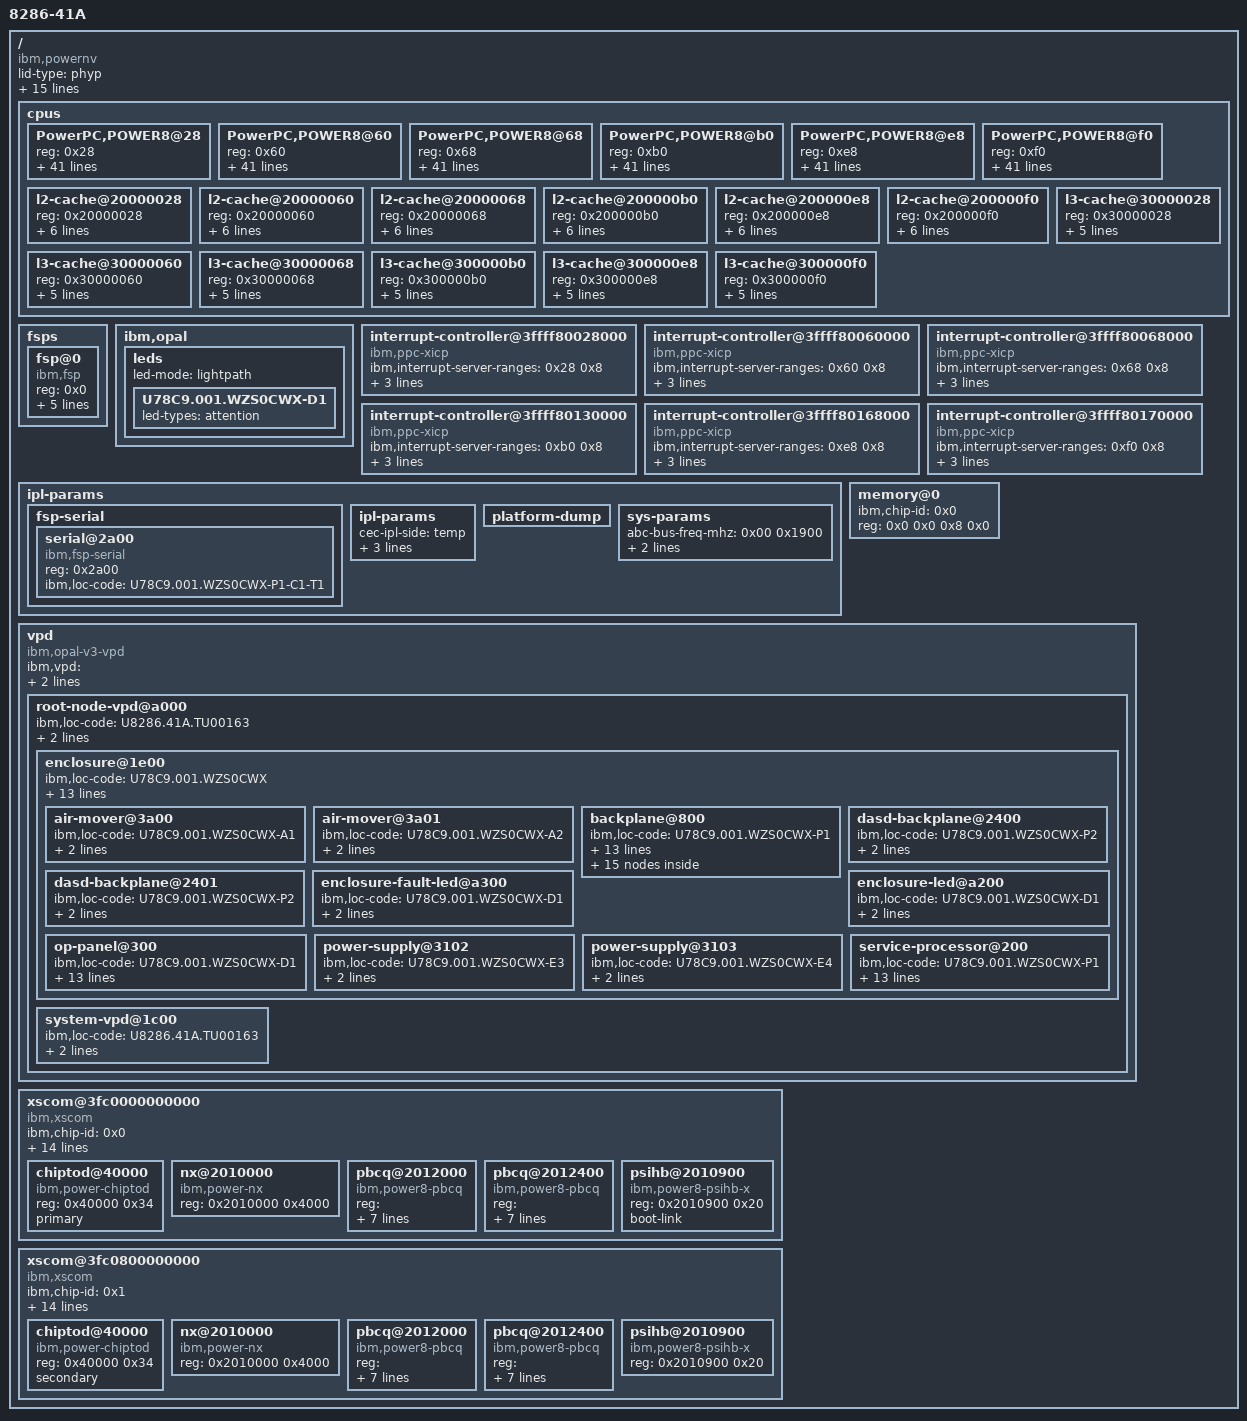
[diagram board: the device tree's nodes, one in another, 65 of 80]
/dts-v1/;

/memreserve/	0x00000007fd510000 0x0000000000190000;
/memreserve/	0x00000007fd6a0000 0x0000000000060000;
/memreserve/	0x00000007fd700000 0x0000000000100000;
/ {
	phandle = <0x1>;
	#address-cells = <0x2>;
	#size-cells = <0x2>;
	lid-type = "phyp";
	compatible = "ibm,powernv", "ibm,firenze";
	nest-frequency = <0x0 0x77359400>;
	vendor = "IBM";
	ibm,io-base-loc-code = "U78C9.001.WZS0CWX-P1";
	ibm,vpd-lx-info = <0x0 0x31000401 0x300043>;
	model = "8286-41A";
	system-id = "TU00163";
	system-brand = "S0";
	model-name = "IBM Power System S814";
	ibm,hbrt-mini-fdt = <0xcafebeef 0x1000 0x31ce42d>;
	reserved-ranges = <0x7 0xfd700000 0x0 0x100000 0x7 0xfd6a0000 0x0 0x60000 0x7 0xfd510000 0x0 0x190000>;
	reserved-names = "ibm,hbrt-vpd-image", "ibm,hbrt-target-image", "ibm,hbrt-code-image";
	ibm,enabled-idle-states = "nap", "fast-sleep", "rvwinkle";

	cpus {
		phandle = <0x22>;
		#address-cells = <0x1>;
		#size-cells = <0x0>;

		PowerPC,POWER8@28 {
			phandle = <0x23>;
			device_type = "cpu";
			status = "okay";
			reg = <0x28>;
			cpu-version = <0x4b0201>;
			64-bit;
			32-64-bridge;
			graphics;
			general-purpose;
			ibm,processor-segment-sizes = <0x1c 0x28 0xffffffff 0xffffffff>;
			ibm,processor-page-sizes = <0xc 0x10 0x18 0x22>;
			ibm,segment-page-sizes = <0xc 0x0 0x3 0xc 0x0 0x10 0x7 0x18 0x38 0x10 0x110 0x2 0x10 0x1 0x18 0x8 0x18 0x100 0x1 0x18 0x0 0x22 0x120 0x1 0x22 0x3>;
			ibm,pa-features = [18 00 f6 3f c7 c0 80 d0 80 00 00 00 00 00 00 00 00 00 80 00 80 00 80 00 80 00];
			ibm,slb-size = <0x20>;
			ibm,vmx = <0x2>;
			ibm,dfp = <0x2>;
			ibm,purr = <0x1>;
			ibm,spurr = <0x1>;
			clock-frequency = <0xb45d1880>;
			ibm,extended-clock-frequency = <0x0 0xb45d1880>;
			timebase-frequency = <0x1e848000>;
			ibm,extended-timebase-frequency = <0x0 0x1e848000>;
			reservation-granule-size = <0x80>;
			d-tlb-size = <0x800>;
			i-tlb-size = <0x0>;
			tlb-size = <0x800>;
			d-tlb-sets = <0x4>;
			i-tlb-sets = <0x0>;
			tlb-sets = <0x4>;
			d-cache-block-size = <0x80>;
			i-cache-block-size = <0x80>;
			d-cache-size = <0x10000>;
			i-cache-size = <0x8000>;
			i-cache-sets = <0x4>;
			d-cache-sets = <0x8>;
			performance-monitor = <0x0 0x1>;
			l2-cache = <0x24>;
			ibm,pir = <0x28>;
			ibm,chip-id = <0x0>;
			ibm,ppc-interrupt-server#s = <0x28 0x29 0x2a 0x2b 0x2c 0x2d 0x2e 0x2f>;
		};

		PowerPC,POWER8@60 {
			phandle = <0x27>;
			device_type = "cpu";
			status = "okay";
			reg = <0x60>;
			cpu-version = <0x4b0201>;
			64-bit;
			32-64-bridge;
			graphics;
			general-purpose;
			ibm,processor-segment-sizes = <0x1c 0x28 0xffffffff 0xffffffff>;
			ibm,processor-page-sizes = <0xc 0x10 0x18 0x22>;
			ibm,segment-page-sizes = <0xc 0x0 0x3 0xc 0x0 0x10 0x7 0x18 0x38 0x10 0x110 0x2 0x10 0x1 0x18 0x8 0x18 0x100 0x1 0x18 0x0 0x22 0x120 0x1 0x22 0x3>;
			ibm,pa-features = [18 00 f6 3f c7 c0 80 d0 80 00 00 00 00 00 00 00 00 00 80 00 80 00 80 00 80 00];
			ibm,slb-size = <0x20>;
			ibm,vmx = <0x2>;
			ibm,dfp = <0x2>;
			ibm,purr = <0x1>;
			ibm,spurr = <0x1>;
			clock-frequency = <0xb45d1880>;
			ibm,extended-clock-frequency = <0x0 0xb45d1880>;
			timebase-frequency = <0x1e848000>;
			ibm,extended-timebase-frequency = <0x0 0x1e848000>;
			reservation-granule-size = <0x80>;
			d-tlb-size = <0x800>;
			i-tlb-size = <0x0>;
			tlb-size = <0x800>;
			d-tlb-sets = <0x4>;
			i-tlb-sets = <0x0>;
			tlb-sets = <0x4>;
			d-cache-block-size = <0x80>;
			i-cache-block-size = <0x80>;
			d-cache-size = <0x10000>;
			i-cache-size = <0x8000>;
			i-cache-sets = <0x4>;
			d-cache-sets = <0x8>;
			performance-monitor = <0x0 0x1>;
			l2-cache = <0x28>;
			ibm,pir = <0x60>;
			ibm,chip-id = <0x0>;
			ibm,ppc-interrupt-server#s = <0x60 0x61 0x62 0x63 0x64 0x65 0x66 0x67>;
		};

		PowerPC,POWER8@68 {
			phandle = <0x2b>;
			device_type = "cpu";
			status = "okay";
			reg = <0x68>;
			cpu-version = <0x4b0201>;
			64-bit;
			32-64-bridge;
			graphics;
			general-purpose;
			ibm,processor-segment-sizes = <0x1c 0x28 0xffffffff 0xffffffff>;
			ibm,processor-page-sizes = <0xc 0x10 0x18 0x22>;
			ibm,segment-page-sizes = <0xc 0x0 0x3 0xc 0x0 0x10 0x7 0x18 0x38 0x10 0x110 0x2 0x10 0x1 0x18 0x8 0x18 0x100 0x1 0x18 0x0 0x22 0x120 0x1 0x22 0x3>;
			ibm,pa-features = [18 00 f6 3f c7 c0 80 d0 80 00 00 00 00 00 00 00 00 00 80 00 80 00 80 00 80 00];
			ibm,slb-size = <0x20>;
			ibm,vmx = <0x2>;
			ibm,dfp = <0x2>;
			ibm,purr = <0x1>;
			ibm,spurr = <0x1>;
			clock-frequency = <0xb45d1880>;
			ibm,extended-clock-frequency = <0x0 0xb45d1880>;
			timebase-frequency = <0x1e848000>;
			ibm,extended-timebase-frequency = <0x0 0x1e848000>;
			reservation-granule-size = <0x80>;
			d-tlb-size = <0x800>;
			i-tlb-size = <0x0>;
			tlb-size = <0x800>;
			d-tlb-sets = <0x4>;
			i-tlb-sets = <0x0>;
			tlb-sets = <0x4>;
			d-cache-block-size = <0x80>;
			i-cache-block-size = <0x80>;
			d-cache-size = <0x10000>;
			i-cache-size = <0x8000>;
			i-cache-sets = <0x4>;
			d-cache-sets = <0x8>;
			performance-monitor = <0x0 0x1>;
			l2-cache = <0x2c>;
			ibm,pir = <0x68>;
			ibm,chip-id = <0x0>;
			ibm,ppc-interrupt-server#s = <0x68 0x69 0x6a 0x6b 0x6c 0x6d 0x6e 0x6f>;
		};

		PowerPC,POWER8@b0 {
			phandle = <0x2f>;
			device_type = "cpu";
			status = "okay";
			reg = <0xb0>;
			cpu-version = <0x4b0201>;
			64-bit;
			32-64-bridge;
			graphics;
			general-purpose;
			ibm,processor-segment-sizes = <0x1c 0x28 0xffffffff 0xffffffff>;
			ibm,processor-page-sizes = <0xc 0x10 0x18 0x22>;
			ibm,segment-page-sizes = <0xc 0x0 0x3 0xc 0x0 0x10 0x7 0x18 0x38 0x10 0x110 0x2 0x10 0x1 0x18 0x8 0x18 0x100 0x1 0x18 0x0 0x22 0x120 0x1 0x22 0x3>;
			ibm,pa-features = [18 00 f6 3f c7 c0 80 d0 80 00 00 00 00 00 00 00 00 00 80 00 80 00 80 00 80 00];
			ibm,slb-size = <0x20>;
			ibm,vmx = <0x2>;
			ibm,dfp = <0x2>;
			ibm,purr = <0x1>;
			ibm,spurr = <0x1>;
			clock-frequency = <0xb45d1880>;
			ibm,extended-clock-frequency = <0x0 0xb45d1880>;
			timebase-frequency = <0x1e848000>;
			ibm,extended-timebase-frequency = <0x0 0x1e848000>;
			reservation-granule-size = <0x80>;
			d-tlb-size = <0x800>;
			i-tlb-size = <0x0>;
			tlb-size = <0x800>;
			d-tlb-sets = <0x4>;
			i-tlb-sets = <0x0>;
			tlb-sets = <0x4>;
			d-cache-block-size = <0x80>;
			i-cache-block-size = <0x80>;
			d-cache-size = <0x10000>;
			i-cache-size = <0x8000>;
			i-cache-sets = <0x4>;
			d-cache-sets = <0x8>;
			performance-monitor = <0x0 0x1>;
			l2-cache = <0x30>;
			ibm,pir = <0xb0>;
			ibm,chip-id = <0x1>;
			ibm,ppc-interrupt-server#s = <0xb0 0xb1 0xb2 0xb3 0xb4 0xb5 0xb6 0xb7>;
		};

		PowerPC,POWER8@e8 {
			phandle = <0x33>;
			device_type = "cpu";
			status = "okay";
			reg = <0xe8>;
			cpu-version = <0x4b0201>;
			64-bit;
			32-64-bridge;
			graphics;
			general-purpose;
			ibm,processor-segment-sizes = <0x1c 0x28 0xffffffff 0xffffffff>;
			ibm,processor-page-sizes = <0xc 0x10 0x18 0x22>;
			ibm,segment-page-sizes = <0xc 0x0 0x3 0xc 0x0 0x10 0x7 0x18 0x38 0x10 0x110 0x2 0x10 0x1 0x18 0x8 0x18 0x100 0x1 0x18 0x0 0x22 0x120 0x1 0x22 0x3>;
			ibm,pa-features = [18 00 f6 3f c7 c0 80 d0 80 00 00 00 00 00 00 00 00 00 80 00 80 00 80 00 80 00];
			ibm,slb-size = <0x20>;
			ibm,vmx = <0x2>;
			ibm,dfp = <0x2>;
			ibm,purr = <0x1>;
			ibm,spurr = <0x1>;
			clock-frequency = <0xb45d1880>;
			ibm,extended-clock-frequency = <0x0 0xb45d1880>;
			timebase-frequency = <0x1e848000>;
			ibm,extended-timebase-frequency = <0x0 0x1e848000>;
			reservation-granule-size = <0x80>;
			d-tlb-size = <0x800>;
			i-tlb-size = <0x0>;
			tlb-size = <0x800>;
			d-tlb-sets = <0x4>;
			i-tlb-sets = <0x0>;
			tlb-sets = <0x4>;
			d-cache-block-size = <0x80>;
			i-cache-block-size = <0x80>;
			d-cache-size = <0x10000>;
			i-cache-size = <0x8000>;
			i-cache-sets = <0x4>;
			d-cache-sets = <0x8>;
			performance-monitor = <0x0 0x1>;
			l2-cache = <0x34>;
			ibm,pir = <0xe8>;
			ibm,chip-id = <0x1>;
			ibm,ppc-interrupt-server#s = <0xe8 0xe9 0xea 0xeb 0xec 0xed 0xee 0xef>;
		};

		PowerPC,POWER8@f0 {
			phandle = <0x37>;
			device_type = "cpu";
			status = "okay";
			reg = <0xf0>;
			cpu-version = <0x4b0201>;
			64-bit;
			32-64-bridge;
			graphics;
			general-purpose;
			ibm,processor-segment-sizes = <0x1c 0x28 0xffffffff 0xffffffff>;
			ibm,processor-page-sizes = <0xc 0x10 0x18 0x22>;
			ibm,segment-page-sizes = <0xc 0x0 0x3 0xc 0x0 0x10 0x7 0x18 0x38 0x10 0x110 0x2 0x10 0x1 0x18 0x8 0x18 0x100 0x1 0x18 0x0 0x22 0x120 0x1 0x22 0x3>;
			ibm,pa-features = [18 00 f6 3f c7 c0 80 d0 80 00 00 00 00 00 00 00 00 00 80 00 80 00 80 00 80 00];
			ibm,slb-size = <0x20>;
			ibm,vmx = <0x2>;
			ibm,dfp = <0x2>;
			ibm,purr = <0x1>;
			ibm,spurr = <0x1>;
			clock-frequency = <0xb45d1880>;
			ibm,extended-clock-frequency = <0x0 0xb45d1880>;
			timebase-frequency = <0x1e848000>;
			ibm,extended-timebase-frequency = <0x0 0x1e848000>;
			reservation-granule-size = <0x80>;
			d-tlb-size = <0x800>;
			i-tlb-size = <0x0>;
			tlb-size = <0x800>;
			d-tlb-sets = <0x4>;
			i-tlb-sets = <0x0>;
			tlb-sets = <0x4>;
			d-cache-block-size = <0x80>;
			i-cache-block-size = <0x80>;
			d-cache-size = <0x10000>;
			i-cache-size = <0x8000>;
			i-cache-sets = <0x4>;
			d-cache-sets = <0x8>;
			performance-monitor = <0x0 0x1>;
			l2-cache = <0x38>;
			ibm,pir = <0xf0>;
			ibm,chip-id = <0x1>;
			ibm,ppc-interrupt-server#s = <0xf0 0xf1 0xf2 0xf3 0xf4 0xf5 0xf6 0xf7>;
		};

		l2-cache@20000028 {
			phandle = <0x24>;
			device_type = "cache";
			reg = <0x20000028>;
			status = "okay";
			cache-unified;
			d-cache-sets = <0x8>;
			i-cache-sets = <0x8>;
			d-cache-size = <0x80000>;
			i-cache-size = <0x80000>;
			l2-cache = <0x25>;
		};

		l2-cache@20000060 {
			phandle = <0x28>;
			device_type = "cache";
			reg = <0x20000060>;
			status = "okay";
			cache-unified;
			d-cache-sets = <0x8>;
			i-cache-sets = <0x8>;
			d-cache-size = <0x80000>;
			i-cache-size = <0x80000>;
			l2-cache = <0x29>;
		};

		l2-cache@20000068 {
			phandle = <0x2c>;
			device_type = "cache";
			reg = <0x20000068>;
			status = "okay";
			cache-unified;
			d-cache-sets = <0x8>;
			i-cache-sets = <0x8>;
			d-cache-size = <0x80000>;
			i-cache-size = <0x80000>;
			l2-cache = <0x2d>;
		};

		l2-cache@200000b0 {
			phandle = <0x30>;
			device_type = "cache";
			reg = <0x200000b0>;
			status = "okay";
			cache-unified;
			d-cache-sets = <0x8>;
			i-cache-sets = <0x8>;
			d-cache-size = <0x80000>;
			i-cache-size = <0x80000>;
			l2-cache = <0x31>;
		};

		l2-cache@200000e8 {
			phandle = <0x34>;
			device_type = "cache";
			reg = <0x200000e8>;
			status = "okay";
			cache-unified;
			d-cache-sets = <0x8>;
			i-cache-sets = <0x8>;
			d-cache-size = <0x80000>;
			i-cache-size = <0x80000>;
			l2-cache = <0x35>;
		};

		l2-cache@200000f0 {
			phandle = <0x38>;
			device_type = "cache";
			reg = <0x200000f0>;
			status = "okay";
			cache-unified;
			d-cache-sets = <0x8>;
			i-cache-sets = <0x8>;
			d-cache-size = <0x80000>;
			i-cache-size = <0x80000>;
			l2-cache = <0x39>;
		};

		l3-cache@30000028 {
			phandle = <0x25>;
			device_type = "cache";
			reg = <0x30000028>;
			status = "okay";
			cache-unified;
			d-cache-sets = <0x8>;
			i-cache-sets = <0x8>;
			d-cache-size = <0x800000>;
			i-cache-size = <0x800000>;
		};

		l3-cache@30000060 {
			phandle = <0x29>;
			device_type = "cache";
			reg = <0x30000060>;
			status = "okay";
			cache-unified;
			d-cache-sets = <0x8>;
			i-cache-sets = <0x8>;
			d-cache-size = <0x800000>;
			i-cache-size = <0x800000>;
		};

		l3-cache@30000068 {
			phandle = <0x2d>;
			device_type = "cache";
			reg = <0x30000068>;
			status = "okay";
			cache-unified;
			d-cache-sets = <0x8>;
			i-cache-sets = <0x8>;
			d-cache-size = <0x800000>;
			i-cache-size = <0x800000>;
		};

		l3-cache@300000b0 {
			phandle = <0x31>;
			device_type = "cache";
			reg = <0x300000b0>;
			status = "okay";
			cache-unified;
			d-cache-sets = <0x8>;
			i-cache-sets = <0x8>;
			d-cache-size = <0x800000>;
			i-cache-size = <0x800000>;
		};

		l3-cache@300000e8 {
			phandle = <0x35>;
			device_type = "cache";
			reg = <0x300000e8>;
			status = "okay";
			cache-unified;
			d-cache-sets = <0x8>;
			i-cache-sets = <0x8>;
			d-cache-size = <0x800000>;
			i-cache-size = <0x800000>;
		};

		l3-cache@300000f0 {
			phandle = <0x39>;
			device_type = "cache";
			reg = <0x300000f0>;
			status = "okay";
			cache-unified;
			d-cache-sets = <0x8>;
			i-cache-sets = <0x8>;
			d-cache-size = <0x800000>;
			i-cache-size = <0x800000>;
		};
	};

	fsps {
		phandle = <0x46>;
		#address-cells = <0x1>;
		#size-cells = <0x0>;

		fsp@0 {
			phandle = <0x47>;
			reg = <0x0>;
			compatible = "ibm,fsp", "ibm,fsp2";
			reg-offset = <0xb0011000>;
			hw-version = <0x2>;
			sw-version = <0x1>;
			primary;
			ibm,psi-links = <0x0>;
		};
	};

	ibm,opal {
		phandle = <0x20>;

		leds {
			phandle = <0x21>;
			led-mode = "lightpath";

			U78C9.001.WZS0CWX-D1 {
				phandle = <0x7000015>;
				led-types = "attention";
			};
		};
	};

	interrupt-controller@3ffff80028000 {
		phandle = <0x26>;
		compatible = "ibm,ppc-xicp", "IBM,power8-icp";
		ibm,interrupt-server-ranges = <0x28 0x8>;
		interrupt-controller;
		reg = <0x3ffff 0x80028000 0x0 0x1000 0x3ffff 0x80029000 0x0 0x1000 0x3ffff 0x8002a000 0x0 0x1000 0x3ffff 0x8002b000 0x0 0x1000 0x3ffff 0x8002c000 0x0 0x1000 0x3ffff 0x8002d000 0x0 0x1000 0x3ffff 0x8002e000 0x0 0x1000 0x3ffff 0x8002f000 0x0 0x1000>;
		#address-cells = <0x0>;
		device_type = "PowerPC-External-Interrupt-Presentation";
	};

	interrupt-controller@3ffff80060000 {
		phandle = <0x2a>;
		compatible = "ibm,ppc-xicp", "IBM,power8-icp";
		ibm,interrupt-server-ranges = <0x60 0x8>;
		interrupt-controller;
		reg = <0x3ffff 0x80060000 0x0 0x1000 0x3ffff 0x80061000 0x0 0x1000 0x3ffff 0x80062000 0x0 0x1000 0x3ffff 0x80063000 0x0 0x1000 0x3ffff 0x80064000 0x0 0x1000 0x3ffff 0x80065000 0x0 0x1000 0x3ffff 0x80066000 0x0 0x1000 0x3ffff 0x80067000 0x0 0x1000>;
		#address-cells = <0x0>;
		device_type = "PowerPC-External-Interrupt-Presentation";
	};

	interrupt-controller@3ffff80068000 {
		phandle = <0x2e>;
		compatible = "ibm,ppc-xicp", "IBM,power8-icp";
		ibm,interrupt-server-ranges = <0x68 0x8>;
		interrupt-controller;
		reg = <0x3ffff 0x80068000 0x0 0x1000 0x3ffff 0x80069000 0x0 0x1000 0x3ffff 0x8006a000 0x0 0x1000 0x3ffff 0x8006b000 0x0 0x1000 0x3ffff 0x8006c000 0x0 0x1000 0x3ffff 0x8006d000 0x0 0x1000 0x3ffff 0x8006e000 0x0 0x1000 0x3ffff 0x8006f000 0x0 0x1000>;
		#address-cells = <0x0>;
		device_type = "PowerPC-External-Interrupt-Presentation";
	};

	interrupt-controller@3ffff80130000 {
		phandle = <0x32>;
		compatible = "ibm,ppc-xicp", "IBM,power8-icp";
		ibm,interrupt-server-ranges = <0xb0 0x8>;
		interrupt-controller;
		reg = <0x3ffff 0x80130000 0x0 0x1000 0x3ffff 0x80131000 0x0 0x1000 0x3ffff 0x80132000 0x0 0x1000 0x3ffff 0x80133000 0x0 0x1000 0x3ffff 0x80134000 0x0 0x1000 0x3ffff 0x80135000 0x0 0x1000 0x3ffff 0x80136000 0x0 0x1000 0x3ffff 0x80137000 0x0 0x1000>;
		#address-cells = <0x0>;
		device_type = "PowerPC-External-Interrupt-Presentation";
	};

	interrupt-controller@3ffff80168000 {
		phandle = <0x36>;
		compatible = "ibm,ppc-xicp", "IBM,power8-icp";
		ibm,interrupt-server-ranges = <0xe8 0x8>;
		interrupt-controller;
		reg = <0x3ffff 0x80168000 0x0 0x1000 0x3ffff 0x80169000 0x0 0x1000 0x3ffff 0x8016a000 0x0 0x1000 0x3ffff 0x8016b000 0x0 0x1000 0x3ffff 0x8016c000 0x0 0x1000 0x3ffff 0x8016d000 0x0 0x1000 0x3ffff 0x8016e000 0x0 0x1000 0x3ffff 0x8016f000 0x0 0x1000>;
		#address-cells = <0x0>;
		device_type = "PowerPC-External-Interrupt-Presentation";
	};

	interrupt-controller@3ffff80170000 {
		phandle = <0x3a>;
		compatible = "ibm,ppc-xicp", "IBM,power8-icp";
		ibm,interrupt-server-ranges = <0xf0 0x8>;
		interrupt-controller;
		reg = <0x3ffff 0x80170000 0x0 0x1000 0x3ffff 0x80171000 0x0 0x1000 0x3ffff 0x80172000 0x0 0x1000 0x3ffff 0x80173000 0x0 0x1000 0x3ffff 0x80174000 0x0 0x1000 0x3ffff 0x80175000 0x0 0x1000 0x3ffff 0x80176000 0x0 0x1000 0x3ffff 0x80177000 0x0 0x1000>;
		#address-cells = <0x0>;
		device_type = "PowerPC-External-Interrupt-Presentation";
	};

	ipl-params {
		phandle = <0x3b>;
		#address-cells = <0x0>;
		#size-cells = <0x0>;

		fsp-serial {
			phandle = <0x3e>;
			#address-cells = <0x1>;
			#size-cells = <0x0>;

			serial@2a00 {
				phandle = <0x3f>;
				reg = <0x2a00>;
				ibm,loc-code = "U78C9.001.WZS0CWX-P1-C1-T1";
				compatible = "ibm,fsp-serial";
			};
		};

		ipl-params {
			phandle = <0x3d>;
			#address-cells = <0x0>;
			#size-cells = <0x0>;
			cec-ipl-side = "temp";
			fsp-ipl-side = "temp";
			os-ipl-mode = <0x0>;
			cec-major-type = "cold";
		};

		platform-dump {
			phandle = <0x40>;
		};

		sys-params {
			phandle = <0x3c>;
			#address-cells = <0x0>;
			#size-cells = <0x0>;
			abc-bus-freq-mhz = < 0x00 0x1900 >;
			ibm,sys-model = " 41A";
			wxyz-bus-freq-mhz = < 0x00 0xfa0 >;

		};
	};

	memory@0 {
		phandle = <0x45>;
		device_type = "memory";
		ibm,chip-id = <0x0>;
		reg = <0x0 0x0 0x8 0x0>;
	};

	vpd {
		phandle = <0x2>;
		compatible = "ibm,opal-v3-vpd";
		#size-cells = <0x0>;
		#address-cells = <0x1>;
		ibm,vpd = <0x84b00052 0x54045653 0x59534452 0x6535953 0x54454d42 0x52025330 0x53450754 0x55303031 0x36335347 0x7202020 0x20202020 0x544d0838 0x3238362d 0x34314154 0x4e082020 0x20202020 0x20204d4e 0x7202020 0x20202020 0x49440220 0x20535506 0x4ac19 0x77064e4e 0x10202020 0x20202020 0x20202020 0x20202020 0x20524704 0xf0c00000 0x52420433 0x20202057 0x4e0c4330 0x35303736 0x30364237 0x30344656 0x20202020 0x20202020 0x20202020 0x20202020 0x20202020 0x20202020 0x20202020 0x20202020 0x20504603 0x78 0x0>;
		ibm,loc-code = "U8286.41A.TU00163";

		root-node-vpd@a000 {
			phandle = <0x3>;
			ibm,loc-code = "U8286.41A.TU00163";
			fru-type = [56 56];
			reg = <0xa000>;
			#size-cells = <0x0>;
			#address-cells = <0x1>;

			enclosure@1e00 {
				phandle = <0x5>;
				ibm,loc-code = "U78C9.001.WZS0CWX";
				fru-type = [45 56];
				reg = <0x1e00>;
				#size-cells = <0x0>;
				#address-cells = <0x1>;
				ibm,vpd = <0x848c0052 0x54045649 0x4e494452 0x10492f4f 0x20424143 0x4b504c41 0x4e452020 0x20434501 0x31565a02 0x3031464e 0x7373459 0x34333434 0x504e0730 0x30453432 0x3431534e 0xc594c33 0x30554635 0x354e3030 0x36434304 0x32434435 0x50520821 0x0 0x48 0x45043030 0x30324354 0x480f300 0x26485702 0x74233 0x6000000 0x142 0x34010042 0x370c0000 0x0 0x0 0x5046 0x2000078 0x841c0052 0x54044c58 0x5230565a 0x230314c 0x58083100 0x4010030 0x435046 0x2000078 0x84440052 0x54045643 0x454e4452 0x6434543 0x20202053 0x4507575a 0x53304357 0x58544d08 0x20202020 0x20202020 0x46430837 0x3843392d 0x30303152 0x470400a0 0xb32c5242 0x4202020 0x20504603 0x78 0x0>;
				fru-number = "74Y4344";
				serial-number = "YL30UF55N006";
				part-number = "00E4241";
				ccin-extension = [31 00];
				hw-version = [00];
				card-type = [80 f3 00];
				hw-characteristics = [00];
				ccin = "2CD5";
				description = "System planar 1S4U";

				air-mover@3a00 {
					phandle = <0xd>;
					ibm,loc-code = "U78C9.001.WZS0CWX-A1";
					fru-type = [41 4d];
					reg = <0x3a00>;
					#size-cells = <0x0>;
					#address-cells = <0x1>;
				};

				air-mover@3a01 {
					phandle = <0xe>;
					ibm,loc-code = "U78C9.001.WZS0CWX-A2";
					fru-type = [41 4d];
					reg = <0x3a01>;
					#size-cells = <0x0>;
					#address-cells = <0x1>;
				};

				backplane@800 {
					phandle = <0x6>;
					ibm,loc-code = "U78C9.001.WZS0CWX-P1";
					fru-type = [42 50];
					reg = <0x800>;
					#size-cells = <0x0>;
					#address-cells = <0x1>;
					ibm,vpd = <0x848c0052 0x54045649 0x4e494452 0x10492f4f 0x20424143 0x4b504c41 0x4e452020 0x20434501 0x31565a02 0x3031464e 0x7373459 0x34333434 0x504e0730 0x30453432 0x3431534e 0xc594c33 0x30554635 0x354e3030 0x36434304 0x32434435 0x50520821 0x0 0x48 0x45043030 0x30324354 0x480f300 0x26485702 0x74233 0x6000000 0x142 0x34010042 0x370c0000 0x0 0x0 0x5046 0x2000078 0x841c0052 0x54044c58 0x5230565a 0x230314c 0x58083100 0x4010030 0x435046 0x2000078 0x0>;
					fru-number = "74Y4344";
					serial-number = "YL30UF55N006";
					part-number = "00E4241";
					ccin-extension = [31 00];
					hw-version = [00];
					card-type = [80 f3 00];
					hw-characteristics = [00];
					ccin = "2CD5";
					description = "System planar 1S4U";

					anchor-card@500 {
						phandle = <0x14>;
						ibm,loc-code = "U78C9.001.WZS0CWX-P1-C13";
						fru-type = [41 56];
						reg = <0x500>;
						#size-cells = <0x0>;
						#address-cells = <0x1>;
						ibm,vpd = <0x84cc0052 0x54045649 0x4e494452 0x10414e43 0x484f5220 0x20202020 0x20202020 0x20434501 0x31565a02 0x3031464e 0x7303045 0x32313532 0x504e0730 0x30453231 0x3438534e 0xc594c31 0x30424733 0x3132314e 0x4a434304 0x35324632 0x50520881 0x300000 0x48 0x45043030 0x31304354 0x440b400 0x485702 0x14233 0x6000000 0x142 0x34010042 0x370c0000 0x0 0x0 0x4239 0x3c435331 0x58150757 0x4e705f53 0x50f139a0 0xbf7efeb7 0x44d314d 0xd7cd74f2 0x862d884d 0x327cb552 0x79809378 0xa24d333e 0x6aed1eb8 0x49dab34d 0x344e1745 0x9bf468e9 0xa1504603 0x78 0x0>;
						fru-number = "00E2152";
						serial-number = "YL10BG3121NJ";
						part-number = "00E2148";
						ccin-extension = [31 00];
						hw-version = [00];
						card-type = [40 b4 00];
						hw-characteristics = [00];
						ccin = "52F2";
						description = "System Anchor Card - IBM Power 814";
					};

					backplane-extender@900 {
						phandle = <0x11>;
						ibm,loc-code = "U78C9.001.WZS0CWX-P1-C1";
						fru-type = [42 58];
						reg = <0x900>;
						#size-cells = <0x0>;
						#address-cells = <0x1>;
						ibm,vpd = <0x84800052 0x54045649 0x4e494452 0x104e4154 0x49564520 0x492f4f20 0x43415244 0x20434501 0x31565a02 0x3031464e 0x7303045 0x31393630 0x504e0730 0x30453338 0x3039534e 0xc594c31 0x30554635 0x3537304c 0x39434304 0x32423042 0x48450430 0x30303143 0x540480b5 0x4857 0x2000142 0x33060000 0x0 0x42340100 0x42370c00 0x0 0x0 0x50 0x46010078 0x0>;
						fru-number = "00E1960";
						serial-number = "YL10UF5570L9";
						part-number = "00E3809";
						ccin-extension = [31 00];
						hw-version = [00];
						card-type = [80 b5 00];
						hw-characteristics = [00];
						ccin = "2B0B";
						description = "Native I/O Card";

						serial-connector@2a00 {
							phandle = <0x1f>;
							ibm,loc-code = "U78C9.001.WZS0CWX-P1-C1-T1";
							fru-type = [43 53];
							reg = <0x2a00>;
							#size-cells = <0x0>;
							#address-cells = <0x1>;
						};

						usb-connector@2900 {
							phandle = <0x1d>;
							ibm,loc-code = "U78C9.001.WZS0CWX-P1-C1-T3";
							fru-type = [43 55];
							reg = <0x2900>;
							#size-cells = <0x0>;
							#address-cells = <0x1>;
						};

						usb-connector@2901 {
							phandle = <0x1e>;
							ibm,loc-code = "U78C9.001.WZS0CWX-P1-C1-T2";
							fru-type = [43 55];
							reg = <0x2901>;
							#size-cells = <0x0>;
							#address-cells = <0x1>;
						};
					};

					hmc-connector@2d00 {
						phandle = <0x19>;
						ibm,loc-code = "U78C9.001.WZS0CWX-P1-T3";
						fru-type = [48 4d];
						reg = <0x2d00>;
						#size-cells = <0x0>;
						#address-cells = <0x1>;
					};

					hmc-connector@2d01 {
						phandle = <0x1a>;
						ibm,loc-code = "U78C9.001.WZS0CWX-P1-T4";
						fru-type = [48 4d];
						reg = <0x2d01>;
						#size-cells = <0x0>;
						#address-cells = <0x1>;
					};

					ms-dimm@d000 {
						phandle = <0x1b>;
						ibm,loc-code = "U78C9.001.WZS0CWX-P1-C16";
						fru-type = [4d 53];
						reg = <0xd000>;
						#size-cells = <0x0>;
						#address-cells = <0x1>;
						ibm,vpd = <0x84940052 0x54045649 0x4e494452 0x1049424d 0x20313647 0x42204d53 0x20202020 0x20434501 0x31565a02 0x3034464e 0x7343154 0x39353735 0x504e0734 0x31543935 0x3735534e 0xc594833 0x314d5333 0x41343031 0x31434304 0x33314530 0x50520849 0x0 0x1000053 0x5a073030 0x31363338 0x34484504 0x30303031 0x43540400 0x48 0x57020090 0x42330600 0x0 0x423401 0x42370c 0x0 0x0 0x0 0x50460078 0x0>;
						fru-number = "41T9575";
						serial-number = "YH31MS3A4011";
						part-number = "41T9575";
						ccin-extension = [31 00];
						hw-version = [00];
						card-type = [00];
						hw-characteristics = [00];
						ccin = "31E0";
						description = "16GB CDIMM";
						ibm,chip-id = <0x0>;
						ibm,memory-bus-frequency = <0x0 0x0>;
						size = "16384";
					};

					ms-dimm@d002 {
						phandle = <0x1c>;
						ibm,loc-code = "U78C9.001.WZS0CWX-P1-C18";
						fru-type = [4d 53];
						reg = <0xd002>;
						#size-cells = <0x0>;
						#address-cells = <0x1>;
						ibm,vpd = <0x84940052 0x54045649 0x4e494452 0x1049424d 0x20313647 0x42204d53 0x20202020 0x20434501 0x31565a02 0x3034464e 0x7343154 0x39353735 0x504e0734 0x31543935 0x3735534e 0xc594833 0x314d5533 0x41433143 0x50434304 0x33314530 0x50520849 0x0 0x1000053 0x5a073030 0x31363338 0x34484504 0x30303031 0x43540400 0x48 0x57020090 0x42330600 0x0 0x423401 0x42370c 0x0 0x0 0x0 0x50460078 0x0>;
						fru-number = "41T9575";
						serial-number = "YH31MU3AC1CP";
						part-number = "41T9575";
						ccin-extension = [31 00];
						hw-version = [00];
						card-type = [00];
						hw-characteristics = [00];
						ccin = "31E0";
						description = "16GB CDIMM";
						ibm,chip-id = <0x0>;
						ibm,memory-bus-frequency = <0x0 0x0>;
						size = "16384";
					};

					processor@1000 {
						phandle = <0x12>;
						ibm,loc-code = "U78C9.001.WZS0CWX-P1-C32";
						fru-type = [50 46];
						reg = <0x1000>;
						#size-cells = <0x0>;
						#address-cells = <0x1>;
						ibm,vpd = [84 8c 00 52 54 04 56 49 4e 49 44 52 10 30 36 2d 57 41 59 20 50 52 4f 43 20 43 55 4f 44 46 4e 07 30 30 46 58 35 32 33 50 4e 07 30 30 46 58 37 34 38 53 4e 0c 59 41 31 39 33 32 30 36 33 35 36 32 43 43 04 35 34 45 31 48 45 04 30 30 30 31 43 54 04 00 00 00 00 48 57 02 00 01 42 33 06 00 00 00 00 00 00 42 34 01 00 42 37 0c 00 00 00 00 00 00 00 00 00 00 00 00 50 52 08 35 00 30 01 44 00 80 01 56 5a 02 30 31 43 45 01 31 50 46 02 00 00 78 00];
						fru-number = "00FX523";
						serial-number = "YA1932063562";
						part-number = "00FX748";
						ccin-extension = [31 00];
						hw-version = [00];
						card-type = [00];
						hw-characteristics = [00];
						ccin = "54E1";
						description = "06-WAY PROC CUOD";
						ibm,chip-id = <0x0>;
					};

					processor@1001 {
						phandle = <0x13>;
						ibm,loc-code = "U78C9.001.WZS0CWX-P1-C32";
						fru-type = [50 46];
						reg = <0x1001>;
						#size-cells = <0x0>;
						#address-cells = <0x1>;
						ibm,vpd = [84 8c 00 52 54 04 56 49 4e 49 44 52 10 30 36 2d 57 41 59 20 50 52 4f 43 20 43 55 4f 44 46 4e 07 30 30 46 58 35 32 33 50 4e 07 30 30 46 58 37 34 38 53 4e 0c 59 41 31 39 33 32 30 36 33 35 36 32 43 43 04 35 34 45 31 48 45 04 30 30 30 31 43 54 04 00 00 00 00 48 57 02 00 01 42 33 06 00 00 00 00 00 00 42 34 01 00 42 37 0c 00 00 00 00 00 00 00 00 00 00 00 00 50 52 08 35 00 30 01 44 00 80 01 56 5a 02 30 31 43 45 01 31 50 46 02 00 00 78 00];
						fru-number = "00FX523";
						serial-number = "YA1932063562";
						part-number = "00FX748";
						ccin-extension = [31 00];
						hw-version = [00];
						card-type = [00];
						hw-characteristics = [00];
						ccin = "54E1";
						description = "06-WAY PROC CUOD";
						ibm,chip-id = <0x1>;
					};

					usb-connector@2902 {
						phandle = <0x15>;
						ibm,loc-code = "U78C9.001.WZS0CWX-P1-T1";
						fru-type = [43 55];
						reg = <0x2902>;
						#size-cells = <0x0>;
						#address-cells = <0x1>;
					};

					usb-connector@2903 {
						phandle = <0x16>;
						ibm,loc-code = "U78C9.001.WZS0CWX-P1-T2";
						fru-type = [43 55];
						reg = <0x2903>;
						#size-cells = <0x0>;
						#address-cells = <0x1>;
					};

					usb-connector@2904 {
						phandle = <0x17>;
						ibm,loc-code = "U78C9.001.WZS0CWX-P1-T5";
						fru-type = [43 55];
						reg = <0x2904>;
						#size-cells = <0x0>;
						#address-cells = <0x1>;
					};

					usb-connector@2905 {
						phandle = <0x18>;
						ibm,loc-code = "U78C9.001.WZS0CWX-P1-T6";
						fru-type = [43 55];
						reg = <0x2905>;
						#size-cells = <0x0>;
						#address-cells = <0x1>;
					};
				};

				dasd-backplane@2400 {
					phandle = <0x9>;
					ibm,loc-code = "U78C9.001.WZS0CWX-P2";
					fru-type = [44 42];
					reg = <0x2400>;
					#size-cells = <0x0>;
					#address-cells = <0x1>;
				};

				dasd-backplane@2401 {
					phandle = <0xa>;
					ibm,loc-code = "U78C9.001.WZS0CWX-P2";
					fru-type = [44 42];
					reg = <0x2401>;
					#size-cells = <0x0>;
					#address-cells = <0x1>;
				};

				enclosure-fault-led@a300 {
					phandle = <0x10>;
					ibm,loc-code = "U78C9.001.WZS0CWX-D1";
					fru-type = [45 46];
					reg = <0xa300>;
					#size-cells = <0x0>;
					#address-cells = <0x1>;
				};

				enclosure-led@a200 {
					phandle = <0xf>;
					ibm,loc-code = "U78C9.001.WZS0CWX-D1";
					fru-type = [45 49];
					reg = <0xa200>;
					#size-cells = <0x0>;
					#address-cells = <0x1>;
				};

				op-panel@300 {
					phandle = <0x8>;
					ibm,loc-code = "U78C9.001.WZS0CWX-D1";
					fru-type = [4f 50];
					reg = <0x300>;
					#size-cells = <0x0>;
					#address-cells = <0x1>;
					ibm,vpd = <0x84800052 0x54045649 0x4e494452 0x10434543 0x204f5020 0x50414e45 0x4c202020 0x20434501 0x31565a02 0x3032464e 0x7303045 0x31393636 0x504e0730 0x30453239 0x3532534e 0xc594c33 0x30554633 0x38453033 0x52434304 0x32423038 0x48450430 0x30303143 0x540480b5 0x4857 0x2000242 0x33060000 0x0 0x42340100 0x42370c00 0x0 0x0 0x50 0x46010078 0x0>;
					fru-number = "00E1966";
					serial-number = "YL30UF38E03R";
					part-number = "00E2952";
					ccin-extension = [31 00];
					hw-version = [00];
					card-type = [80 b5 00];
					hw-characteristics = [00];
					ccin = "2B08";
					description = "CEC OP PANEL";
				};

				power-supply@3102 {
					phandle = <0xb>;
					ibm,loc-code = "U78C9.001.WZS0CWX-E3";
					fru-type = [50 53];
					reg = <0x3102>;
					#size-cells = <0x0>;
					#address-cells = <0x1>;
				};

				power-supply@3103 {
					phandle = <0xc>;
					ibm,loc-code = "U78C9.001.WZS0CWX-E4";
					fru-type = [50 53];
					reg = <0x3103>;
					#size-cells = <0x0>;
					#address-cells = <0x1>;
				};

				service-processor@200 {
					phandle = <0x7>;
					ibm,loc-code = "U78C9.001.WZS0CWX-P1";
					fru-type = [53 50];
					reg = <0x200>;
					#size-cells = <0x0>;
					#address-cells = <0x1>;
					ibm,vpd = <0x848c0052 0x54045649 0x4e494452 0x10492f4f 0x20424143 0x4b504c41 0x4e452020 0x20434501 0x31565a02 0x3031464e 0x7373459 0x34333434 0x504e0730 0x30453432 0x3431534e 0xc594c33 0x30554635 0x354e3030 0x36434304 0x32434435 0x50520821 0x0 0x48 0x45043030 0x30324354 0x480f300 0x26485702 0x74233 0x6000000 0x142 0x34010042 0x370c0000 0x0 0x0 0x5046 0x2000078 0x841c0052 0x54044c58 0x5230565a 0x230314c 0x58083100 0x4010030 0x435046 0x2000078 0x84500052 0x54045652 0x31304452 0x10465350 0x20202020 0x20202020 0x20202020 0x20464704 0x564e5350 0x44430f42 0x44203230 0x31323032 0x32303038 0x3030464c 0x14503120 0x20202020 0x20202020 0x20202020 0x20202020 0x20504603 0x78 0x84400052 0x54045657 0x31304452 0x10465350 0x20565731 0x30202020 0x20202020 0x20474420 0x0 0x0 0x0 0x0 0x0 0x0 0x0 0x0 0x50460078 0x0>;
					fru-number = "74Y4344";
					serial-number = "YL30UF55N006";
					part-number = "00E4241";
					ccin-extension = [31 00];
					hw-version = [00];
					card-type = [80 f3 00];
					hw-characteristics = [00];
					ccin = "2CD5";
					description = "System planar 1S4U";
				};
			};

			system-vpd@1c00 {
				phandle = <0x4>;
				ibm,loc-code = "U8286.41A.TU00163";
				fru-type = [53 56];
				reg = <0x1c00>;
				#size-cells = <0x0>;
				#address-cells = <0x1>;
			};
		};
	};

	xscom@3fc0000000000 {
		phandle = <0x41>;
		ibm,chip-id = <0x0>;
		ibm,proc-chip-id = <0x0>;
		#address-cells = <0x1>;
		#size-cells = <0x1>;
		scom-controller;
		compatible = "ibm,xscom", "ibm,power8-xscom";
		reg = <0x3fc00 0x0 0x8 0x0>;
		bus-frequency = <0x0 0x1dcd6500>;
		ibm,dbob-id = <0x0>;
		ibm,occ-functional-state = <0x1>;
		ibm,loc-code = "U78C9.001.WZS0CWX-P1-C32";
		ibm,module-vpd = <0xcafebeef 0x10000 0xa502aa2f>;
		part-number = "00KV631";
		serial-number = "YA1932063562";
		ibm,ccm-node-id = <0x0>;
		ibm,hw-card-id = <0x0>;
		ibm,hw-module-id = <0x0>;
		ibm,mem-interleave-scope = <0x0>;

		chiptod@40000 {
			phandle = <0x48>;
			reg = <0x40000 0x34>;
			compatible = "ibm,power-chiptod", "ibm,power8-chiptod";
			primary;
		};

		nx@2010000 {
			phandle = <0x4a>;
			compatible = "ibm,power-nx", "ibm,power8-nx";
			reg = <0x2010000 0x4000>;
		};

		pbcq@2012000 {
			phandle = <0x4c>;
			reg = <0x2012000 0x20 0x9012000 0x05 0x9013c00 0x15>;
			compatible = "ibm,power8-pbcq";
			ibm,phb-index = <0x0>;
			ibm,hub-id = <0x0>;
			ibm,loc-code = "U78C9.001.WZS0CWX-P1-C32";
			ibm,use-ab-detect;
			ibm,lane-eq = <0x77777777 0x77777777 0x77777777 0x77777777 0x77777777 0x77777777 0x77777777 0x77777777>;
		};

		pbcq@2012400 {
			phandle = <0x4d>;
			reg = <0x2012400 0x20 0x9012400 0x05 0x9013c40 0x15>;
			compatible = "ibm,power8-pbcq";
			ibm,phb-index = <0x1>;
			ibm,hub-id = <0x0>;
			ibm,loc-code = "U78C9.001.WZS0CWX-P1-C32";
			ibm,use-ab-detect;
			ibm,lane-eq = <0x77777777 0x77777777 0x77777777 0x77777777 0x0 0x0 0x0 0x0>;
		};

		psihb@2010900 {
			phandle = <0x42>;
			reg = <0x2010900 0x20>;
			compatible = "ibm,power8-psihb-x", "ibm,psihb-x";
			boot-link;
			status = "ok";
		};
	};

	xscom@3fc0800000000 {
		phandle = <0x43>;
		ibm,chip-id = <0x1>;
		ibm,proc-chip-id = <0x1>;
		#address-cells = <0x1>;
		#size-cells = <0x1>;
		scom-controller;
		compatible = "ibm,xscom", "ibm,power8-xscom";
		reg = <0x3fc08 0x0 0x8 0x0>;
		bus-frequency = <0x0 0x1dcd6500>;
		ibm,dbob-id = <0x0>;
		ibm,occ-functional-state = <0x1>;
		ibm,loc-code = "U78C9.001.WZS0CWX-P1-C32";
		ibm,module-vpd = <0xcafebeef 0x10000 0x9f87fa41>;
		part-number = "00KV631";
		serial-number = "YA1932063562";
		ibm,ccm-node-id = <0x0>;
		ibm,hw-card-id = <0x0>;
		ibm,hw-module-id = <0x0>;
		ibm,mem-interleave-scope = <0x0>;

		chiptod@40000 {
			phandle = <0x49>;
			reg = <0x40000 0x34>;
			compatible = "ibm,power-chiptod", "ibm,power8-chiptod";
			secondary;
		};

		nx@2010000 {
			phandle = <0x4b>;
			compatible = "ibm,power-nx", "ibm,power8-nx";
			reg = <0x2010000 0x4000>;
		};

		pbcq@2012000 {
			phandle = <0x4e>;
			reg = <0x2012000 0x20 0x9012000 0x05 0x9013c00 0x15>;
			compatible = "ibm,power8-pbcq";
			ibm,phb-index = <0x0>;
			ibm,hub-id = <0x1>;
			ibm,loc-code = "U78C9.001.WZS0CWX-P1-C32";
			ibm,use-ab-detect;
			ibm,lane-eq = <0x77777777 0x77777777 0x77777777 0x77777777 0x77777777 0x77777777 0x77777777 0x77777777>;
		};

		pbcq@2012400 {
			phandle = <0x4f>;
			reg = <0x2012400 0x20 0x9012400 0x05 0x9013c40 0x15>;
			compatible = "ibm,power8-pbcq";
			ibm,phb-index = <0x1>;
			ibm,hub-id = <0x1>;
			ibm,loc-code = "U78C9.001.WZS0CWX-P1-C32";
			ibm,use-ab-detect;
			ibm,lane-eq = <0x68686868 0x68686868 0x68686868 0x68686868 0x0 0x0 0x0 0x0>;
		};

		psihb@2010900 {
			phandle = <0x44>;
			reg = <0x2010900 0x20>;
			compatible = "ibm,power8-psihb-x", "ibm,psihb-x";
		};
	};
};
